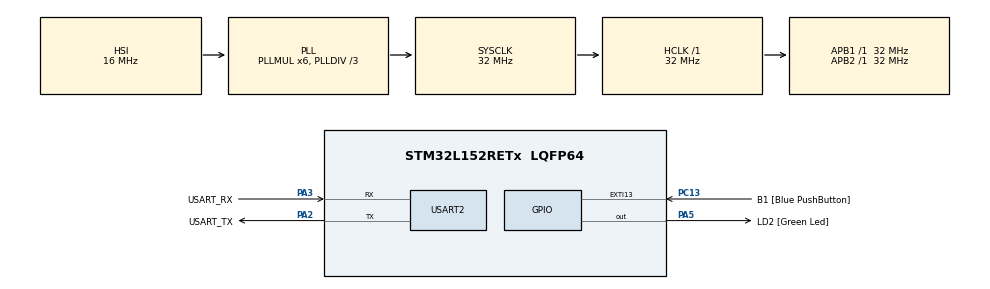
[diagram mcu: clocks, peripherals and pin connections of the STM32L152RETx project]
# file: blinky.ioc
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FREERTOS.Queues01=eventQueue,16,uint16_t,0,Dynamic,NULL,NULL
FREERTOS.Tasks01=defaultTask,0,128,StartDefaultTask,Default,NULL,Dynamic,NULL,NULL;ledTask,-3,128,StartLedTask,Default,NULL,Dynamic,NULL,NULL;buttonTask,-3,128,StartButtonTask,Default,NULL,Dynamic,NULL,NULL
Mcu.Family=STM32L1
Mcu.Name=STM32L152RETx
Mcu.Package=LQFP64
NVIC.PriorityGroup=NVIC_PRIORITYGROUP_4
NVIC.TIM2_IRQn=true\:0\:0\:false\:false\:true\:false\:false\:true
NVIC.TimeBase=TIM2_IRQn
NVIC.TimeBaseIP=TIM2
PA13.GPIO_Label=TMS
PA13.Mode=Serial_Wire
PA13.Signal=SYS_JTMS-SWDIO
PA14.GPIO_Label=TCK
PA14.Mode=Serial_Wire
PA14.Signal=SYS_JTCK-SWCLK
PA2.GPIO_Label=USART_TX
PA2.Mode=Asynchronous
PA2.Signal=USART2_TX
PA3.GPIO_Label=USART_RX
PA3.Mode=Asynchronous
PA3.Signal=USART2_RX
PA5.GPIO_Label=LD2 [Green Led]
PA5.Signal=GPIO_Output
PB3.GPIO_Label=SWO
PB3.Signal=SYS_JTDO-TRACESWO
PC13-WKUP2.GPIO_Label=B1 [Blue PushButton]
PC13-WKUP2.Signal=GPXTI13
PC14-OSC32_IN.Mode=LSE-External-Oscillator
PC14-OSC32_IN.Signal=RCC_OSC32_IN
PC15-OSC32_OUT.Mode=LSE-External-Oscillator
PC15-OSC32_OUT.Signal=RCC_OSC32_OUT
PH0-OSC_IN.Mode=HSE-External-Clock-Source
PH0-OSC_IN.Signal=RCC_OSC_IN
PH1-OSC_OUT.Signal=RCC_OSC_OUT
ProjectManager.HeapSize=0x200
ProjectManager.StackSize=0x400
ProjectManager.TargetToolchain=TrueSTUDIO
RCC.48MHZClocksFreq_Value=48000000
RCC.AHBFreq_Value=32000000
RCC.APB1Freq_Value=32000000
RCC.APB1TimFreq_Value=32000000
RCC.APB2Freq_Value=32000000
RCC.APB2TimFreq_Value=32000000
RCC.HCLKFreq_Value=32000000
RCC.HSE_VALUE=8000000
RCC.HSI_VALUE=16000000
RCC.MSI_VALUE=2097000
RCC.PLLDIV=RCC_PLL_DIV3
RCC.PLLMUL=RCC_PLL_MUL6
RCC.RTCClockSelectionVirtual=RCC_RTCCLKSOURCE_LSE
RCC.SYSCLKFreq_VALUE=32000000
RCC.SYSCLKSource=RCC_SYSCLKSOURCE_PLLCLK
RCC.USBOutput=48000000
RCC.VCOOutputFreq_Value=96000000
USART2.VirtualMode=VM_ASYNC
VP_FREERTOS_VS_CMSIS_V1.Mode=CMSIS_V1
VP_SYS_VS_tim2.Mode=TIM2
board=NUCLEO-L152RE

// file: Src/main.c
/* USER CODE BEGIN Header */
/**
  ******************************************************************************
  * @file           : main.c
  * @brief          : Main program body
  ******************************************************************************
  * @attention
  *
  * <h2><center>&copy; Copyright (c) 2019 STMicroelectronics.
  * All rights reserved.</center></h2>
  *
  * This software component is licensed by ST under BSD 3-Clause license,
  * the "License"; You may not use this file except in compliance with the
  * License. You may obtain a copy of the License at:
  *                        opensource.org/licenses/BSD-3-Clause
  *
  ******************************************************************************
  */
/* USER CODE END Header */

#include "main.h"
#include "cmsis_os.h"

UART_HandleTypeDef huart2;

osThreadId defaultTaskHandle;
osThreadId ledTaskHandle;
osThreadId buttonTaskHandle;
osMessageQId eventQueueHandle;

void SystemClock_Config(void);
static void MX_GPIO_Init(void);
static void MX_USART2_UART_Init(void);
void StartDefaultTask(void const * argument);
void StartLedTask(void const * argument);
void StartButtonTask(void const * argument);

int main(void)
{

  /* MCU Configuration--------------------------------------------------------*/

  /* Reset of all peripherals, Initializes the Flash interface and the Systick. */
  HAL_Init();

  /* Configure the system clock */
  SystemClock_Config();

  /* Initialize all configured peripherals */
  MX_GPIO_Init();
  MX_USART2_UART_Init();

  /* Create the queue(s) */
  /* definition and creation of eventQueue */
  osMessageQDef(eventQueue, 16, uint16_t);
  eventQueueHandle = osMessageCreate(osMessageQ(eventQueue), NULL);

  /* Create the thread(s) */
  /* definition and creation of defaultTask */
  osThreadDef(defaultTask, StartDefaultTask, osPriorityNormal, 0, 128);
  defaultTaskHandle = osThreadCreate(osThread(defaultTask), NULL);

  /* definition and creation of ledTask */
  osThreadDef(ledTask, StartLedTask, osPriorityIdle, 0, 128);
  ledTaskHandle = osThreadCreate(osThread(ledTask), NULL);

  /* definition and creation of buttonTask */
  osThreadDef(buttonTask, StartButtonTask, osPriorityIdle, 0, 128);
  buttonTaskHandle = osThreadCreate(osThread(buttonTask), NULL);

  /* Start scheduler */
  osKernelStart();

  /* We should never get here as control is now taken by the scheduler */

  /* Infinite loop */
  while (1)
  {

  }
}

void SystemClock_Config(void)
{
  RCC_OscInitTypeDef RCC_OscInitStruct = {0};
  RCC_ClkInitTypeDef RCC_ClkInitStruct = {0};

  /** Configure the main internal regulator output voltage
  */
  __HAL_PWR_VOLTAGESCALING_CONFIG(PWR_REGULATOR_VOLTAGE_SCALE1);
  /** Initializes the CPU, AHB and APB busses clocks
  */
  RCC_OscInitStruct.OscillatorType = RCC_OSCILLATORTYPE_HSI;
  RCC_OscInitStruct.HSIState = RCC_HSI_ON;
  RCC_OscInitStruct.HSICalibrationValue = RCC_HSICALIBRATION_DEFAULT;
  RCC_OscInitStruct.PLL.PLLState = RCC_PLL_ON;
  RCC_OscInitStruct.PLL.PLLSource = RCC_PLLSOURCE_HSI;
  RCC_OscInitStruct.PLL.PLLMUL = RCC_PLL_MUL6;
  RCC_OscInitStruct.PLL.PLLDIV = RCC_PLL_DIV3;
  if (HAL_RCC_OscConfig(&RCC_OscInitStruct) != HAL_OK)
  {
    Error_Handler();
  }
  /** Initializes the CPU, AHB and APB busses clocks
  */
  RCC_ClkInitStruct.ClockType = RCC_CLOCKTYPE_HCLK|RCC_CLOCKTYPE_SYSCLK
                              |RCC_CLOCKTYPE_PCLK1|RCC_CLOCKTYPE_PCLK2;
  RCC_ClkInitStruct.SYSCLKSource = RCC_SYSCLKSOURCE_PLLCLK;
  RCC_ClkInitStruct.AHBCLKDivider = RCC_SYSCLK_DIV1;
  RCC_ClkInitStruct.APB1CLKDivider = RCC_HCLK_DIV1;
  RCC_ClkInitStruct.APB2CLKDivider = RCC_HCLK_DIV1;

  if (HAL_RCC_ClockConfig(&RCC_ClkInitStruct, FLASH_LATENCY_1) != HAL_OK)
  {
    Error_Handler();
  }
}

static void MX_USART2_UART_Init(void)
{

  huart2.Instance = USART2;
  huart2.Init.BaudRate = 115200;
  huart2.Init.WordLength = UART_WORDLENGTH_8B;
  huart2.Init.StopBits = UART_STOPBITS_1;
  huart2.Init.Parity = UART_PARITY_NONE;
  huart2.Init.Mode = UART_MODE_TX_RX;
  huart2.Init.HwFlowCtl = UART_HWCONTROL_NONE;
  huart2.Init.OverSampling = UART_OVERSAMPLING_16;
  if (HAL_UART_Init(&huart2) != HAL_OK)
  {
    Error_Handler();
  }

}

static void MX_GPIO_Init(void)
{
  GPIO_InitTypeDef GPIO_InitStruct = {0};

  /* GPIO Ports Clock Enable */
  __HAL_RCC_GPIOC_CLK_ENABLE();
  __HAL_RCC_GPIOH_CLK_ENABLE();
  __HAL_RCC_GPIOA_CLK_ENABLE();
  __HAL_RCC_GPIOB_CLK_ENABLE();

  /*Configure GPIO pin Output Level */
  HAL_GPIO_WritePin(LD2_GPIO_Port, LD2_Pin, GPIO_PIN_RESET);

  /*Configure GPIO pin : B1_Pin */
  GPIO_InitStruct.Pin = B1_Pin;
  GPIO_InitStruct.Mode = GPIO_MODE_IT_RISING;
  GPIO_InitStruct.Pull = GPIO_NOPULL;
  HAL_GPIO_Init(B1_GPIO_Port, &GPIO_InitStruct);

  /*Configure GPIO pin : LD2_Pin */
  GPIO_InitStruct.Pin = LD2_Pin;
  GPIO_InitStruct.Mode = GPIO_MODE_OUTPUT_PP;
  GPIO_InitStruct.Pull = GPIO_NOPULL;
  GPIO_InitStruct.Speed = GPIO_SPEED_FREQ_LOW;
  HAL_GPIO_Init(LD2_GPIO_Port, &GPIO_InitStruct);

}

void StartDefaultTask(void const * argument)
{

  for(;;)
  {
	  osDelay(1);
  }
}

void StartLedTask(void const * argument)
{
  /* USER CODE BEGIN StartLedTask */
  /* Infinite loop */
  for(;;)
  {
    osDelay(30);
  }
  /* USER CODE END StartLedTask */
}

void StartButtonTask(void const * argument)
{
  /* USER CODE BEGIN StartButtonTask */
	int test, i;
	test = 0;
  /* Infinite loop */
  for(;;)
  {

    if(HAL_GPIO_ReadPin(B1_GPIO_Port, B1_Pin) == GPIO_PIN_RESET) {
      test ++;
      HAL_GPIO_WritePin(LD2_GPIO_Port, LD2_Pin, GPIO_PIN_SET);
    } else {
    	HAL_GPIO_WritePin(LD2_GPIO_Port, LD2_Pin, GPIO_PIN_RESET);
    }

  }
  /* USER CODE END StartButtonTask */
}

void HAL_TIM_PeriodElapsedCallback(TIM_HandleTypeDef *htim)
{
  if (htim->Instance == TIM2) {
    HAL_IncTick();
  }
}

void Error_Handler(void)
{
}

/************************ (C) COPYRIGHT STMicroelectronics *****END OF FILE****/
